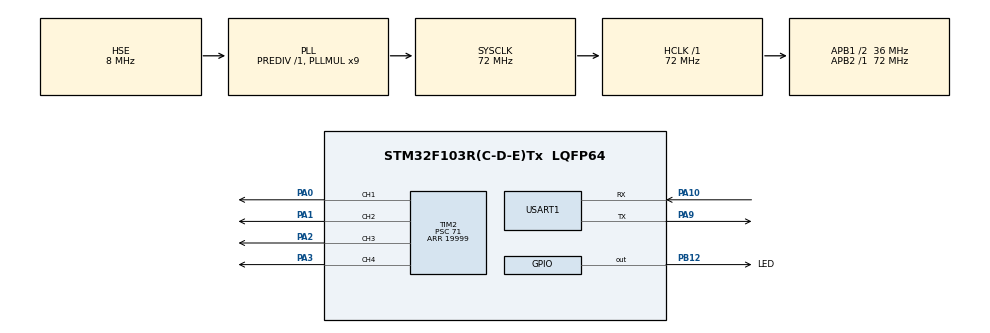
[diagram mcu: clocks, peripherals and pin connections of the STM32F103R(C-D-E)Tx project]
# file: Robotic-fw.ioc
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Dma.Request0=USART1_RX
Dma.Request1=USART1_TX
Dma.USART1_RX.0.Direction=DMA_PERIPH_TO_MEMORY
Dma.USART1_RX.0.Instance=DMA1_Channel5
Dma.USART1_RX.0.MemDataAlignment=DMA_MDATAALIGN_BYTE
Dma.USART1_RX.0.MemInc=DMA_MINC_ENABLE
Dma.USART1_RX.0.Mode=DMA_NORMAL
Dma.USART1_RX.0.PeriphDataAlignment=DMA_PDATAALIGN_BYTE
Dma.USART1_RX.0.PeriphInc=DMA_PINC_DISABLE
Dma.USART1_RX.0.Priority=DMA_PRIORITY_LOW
Dma.USART1_TX.1.Direction=DMA_MEMORY_TO_PERIPH
Dma.USART1_TX.1.Instance=DMA1_Channel4
Dma.USART1_TX.1.MemDataAlignment=DMA_MDATAALIGN_BYTE
Dma.USART1_TX.1.MemInc=DMA_MINC_ENABLE
Dma.USART1_TX.1.Mode=DMA_NORMAL
Dma.USART1_TX.1.PeriphDataAlignment=DMA_PDATAALIGN_BYTE
Dma.USART1_TX.1.PeriphInc=DMA_PINC_DISABLE
Dma.USART1_TX.1.Priority=DMA_PRIORITY_LOW
Mcu.Family=STM32F1
Mcu.Name=STM32F103R(C-D-E)Tx
Mcu.Package=LQFP64
NVIC.DMA1_Channel4_IRQn=true\:0\:0\:false\:false\:true\:false\:true\:true
NVIC.DMA1_Channel5_IRQn=true\:0\:0\:false\:false\:true\:false\:true\:true
NVIC.PriorityGroup=NVIC_PRIORITYGROUP_4
NVIC.USART1_IRQn=true\:0\:0\:false\:false\:true\:false\:true\:true
PA0-WKUP.Signal=S_TIM2_CH1_ETR
PA1.Signal=S_TIM2_CH2
PA10.Mode=Asynchronous
PA10.Signal=USART1_RX
PA13.Mode=Serial_Wire
PA13.Signal=SYS_JTMS-SWDIO
PA14.Mode=Serial_Wire
PA14.Signal=SYS_JTCK-SWCLK
PA2.Signal=S_TIM2_CH3
PA3.Signal=S_TIM2_CH4
PA9.Mode=Asynchronous
PA9.Signal=USART1_TX
PB12.GPIO_Label=LED
PB12.Signal=GPIO_Output
PD0-OSC_IN.Mode=HSE-External-Oscillator
PD0-OSC_IN.Signal=RCC_OSC_IN
PD1-OSC_OUT.Mode=HSE-External-Oscillator
PD1-OSC_OUT.Signal=RCC_OSC_OUT
ProjectManager.HeapSize=0x200
ProjectManager.StackSize=0x400
ProjectManager.TargetToolchain=STM32CubeIDE
RCC.AHBFreq_Value=72000000
RCC.APB1CLKDivider=RCC_HCLK_DIV2
RCC.APB1Freq_Value=36000000
RCC.APB1TimFreq_Value=72000000
RCC.APB2Freq_Value=72000000
RCC.APB2TimFreq_Value=72000000
RCC.DATA_CACHE_ENABLE=0
RCC.HCLKFreq_Value=72000000
RCC.INSTRUCTION_CACHE_ENABLE=0
RCC.PLLMUL=RCC_PLL_MUL9
RCC.PLLSourceVirtual=RCC_PLLSOURCE_HSE
RCC.SYSCLKFreq_VALUE=72000000
RCC.SYSCLKSource=RCC_SYSCLKSOURCE_PLLCLK
RCC.USBFreq_Value=72000000
SH.S_TIM2_CH1_ETR.0=TIM2_CH1,PWM Generation1 CH1
SH.S_TIM2_CH2.0=TIM2_CH2,PWM Generation2 CH2
SH.S_TIM2_CH3.0=TIM2_CH3,PWM Generation3 CH3
SH.S_TIM2_CH4.0=TIM2_CH4,PWM Generation4 CH4
TIM2.Channel-PWM\ Generation1\ CH1=TIM_CHANNEL_1
TIM2.Channel-PWM\ Generation2\ CH2=TIM_CHANNEL_2
TIM2.Channel-PWM\ Generation3\ CH3=TIM_CHANNEL_3
TIM2.Channel-PWM\ Generation4\ CH4=TIM_CHANNEL_4
TIM2.Period=19999
TIM2.Prescaler=71
USART1.VirtualMode=VM_ASYNC
board=custom

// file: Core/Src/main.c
/* USER CODE BEGIN Header */
/**
  ******************************************************************************
  * @file           : main.c
  * @brief          : Main program body
  ******************************************************************************
  * @attention
  *
  * Copyright (c) 2024 STMicroelectronics.
  * All rights reserved.
  *
  * This software is licensed under terms that can be found in the LICENSE file
  * in the root directory of this software component.
  * If no LICENSE file comes with this software, it is provided AS-IS.
  *
  ******************************************************************************
  */
/* USER CODE END Header */
#include "main.h"

/* USER CODE BEGIN PD */
unit8_t USART3_RXbuff;
extern unit8_t center_x, center_y, color_type;
extern double center_x_cm, center_y_cm;
/* USER CODE END PD */

TIM_HandleTypeDef htim2;

UART_HandleTypeDef huart1;
DMA_HandleTypeDef hdma_usart1_rx;
DMA_HandleTypeDef hdma_usart1_tx;

void SystemClock_Config(void);
static void MX_GPIO_Init(void);
static void MX_DMA_Init(void);
static void MX_TIM2_Init(void);
static void MX_USART1_UART_Init(void);

int main(void)
{

  /* MCU Configuration--------------------------------------------------------*/

  /* Reset of all peripherals, Initializes the Flash interface and the Systick. */
  HAL_Init();

  /* Configure the system clock */
  SystemClock_Config();

  /* Initialize all configured peripherals */
  MX_GPIO_Init();
  MX_DMA_Init();
  MX_TIM2_Init();
  MX_USART1_UART_Init();

  /* Infinite loop */
  while (1)
  {

  }
}

void SystemClock_Config(void)
{
  RCC_OscInitTypeDef RCC_OscInitStruct = {0};
  RCC_ClkInitTypeDef RCC_ClkInitStruct = {0};

  /** Initializes the RCC Oscillators according to the specified parameters
  * in the RCC_OscInitTypeDef structure.
  */
  RCC_OscInitStruct.OscillatorType = RCC_OSCILLATORTYPE_HSE;
  RCC_OscInitStruct.HSEState = RCC_HSE_ON;
  RCC_OscInitStruct.HSEPredivValue = RCC_HSE_PREDIV_DIV1;
  RCC_OscInitStruct.HSIState = RCC_HSI_ON;
  RCC_OscInitStruct.PLL.PLLState = RCC_PLL_ON;
  RCC_OscInitStruct.PLL.PLLSource = RCC_PLLSOURCE_HSE;
  RCC_OscInitStruct.PLL.PLLMUL = RCC_PLL_MUL9;
  if (HAL_RCC_OscConfig(&RCC_OscInitStruct) != HAL_OK)
  {
    Error_Handler();
  }

  /** Initializes the CPU, AHB and APB buses clocks
  */
  RCC_ClkInitStruct.ClockType = RCC_CLOCKTYPE_HCLK|RCC_CLOCKTYPE_SYSCLK
                              |RCC_CLOCKTYPE_PCLK1|RCC_CLOCKTYPE_PCLK2;
  RCC_ClkInitStruct.SYSCLKSource = RCC_SYSCLKSOURCE_PLLCLK;
  RCC_ClkInitStruct.AHBCLKDivider = RCC_SYSCLK_DIV1;
  RCC_ClkInitStruct.APB1CLKDivider = RCC_HCLK_DIV2;
  RCC_ClkInitStruct.APB2CLKDivider = RCC_HCLK_DIV1;

  if (HAL_RCC_ClockConfig(&RCC_ClkInitStruct, FLASH_LATENCY_2) != HAL_OK)
  {
    Error_Handler();
  }
}

static void MX_TIM2_Init(void)
{

  TIM_MasterConfigTypeDef sMasterConfig = {0};
  TIM_OC_InitTypeDef sConfigOC = {0};

  htim2.Instance = TIM2;
  htim2.Init.Prescaler = 71;
  htim2.Init.CounterMode = TIM_COUNTERMODE_UP;
  htim2.Init.Period = 19999;
  htim2.Init.ClockDivision = TIM_CLOCKDIVISION_DIV1;
  htim2.Init.AutoReloadPreload = TIM_AUTORELOAD_PRELOAD_DISABLE;
  if (HAL_TIM_PWM_Init(&htim2) != HAL_OK)
  {
    Error_Handler();
  }
  sMasterConfig.MasterOutputTrigger = TIM_TRGO_RESET;
  sMasterConfig.MasterSlaveMode = TIM_MASTERSLAVEMODE_DISABLE;
  if (HAL_TIMEx_MasterConfigSynchronization(&htim2, &sMasterConfig) != HAL_OK)
  {
    Error_Handler();
  }
  sConfigOC.OCMode = TIM_OCMODE_PWM1;
  sConfigOC.Pulse = 0;
  sConfigOC.OCPolarity = TIM_OCPOLARITY_HIGH;
  sConfigOC.OCFastMode = TIM_OCFAST_DISABLE;
  if (HAL_TIM_PWM_ConfigChannel(&htim2, &sConfigOC, TIM_CHANNEL_1) != HAL_OK)
  {
    Error_Handler();
  }
  if (HAL_TIM_PWM_ConfigChannel(&htim2, &sConfigOC, TIM_CHANNEL_2) != HAL_OK)
  {
    Error_Handler();
  }
  if (HAL_TIM_PWM_ConfigChannel(&htim2, &sConfigOC, TIM_CHANNEL_3) != HAL_OK)
  {
    Error_Handler();
  }
  if (HAL_TIM_PWM_ConfigChannel(&htim2, &sConfigOC, TIM_CHANNEL_4) != HAL_OK)
  {
    Error_Handler();
  }
  HAL_TIM_MspPostInit(&htim2);

}

static void MX_USART1_UART_Init(void)
{

  huart1.Instance = USART1;
  huart1.Init.BaudRate = 115200;
  huart1.Init.WordLength = UART_WORDLENGTH_8B;
  huart1.Init.StopBits = UART_STOPBITS_1;
  huart1.Init.Parity = UART_PARITY_NONE;
  huart1.Init.Mode = UART_MODE_TX_RX;
  huart1.Init.HwFlowCtl = UART_HWCONTROL_NONE;
  huart1.Init.OverSampling = UART_OVERSAMPLING_16;
  if (HAL_UART_Init(&huart1) != HAL_OK)
  {
    Error_Handler();
  }

}

static void MX_DMA_Init(void)
{

  /* DMA controller clock enable */
  __HAL_RCC_DMA1_CLK_ENABLE();

  /* DMA interrupt init */
  /* DMA1_Channel4_IRQn interrupt configuration */
  HAL_NVIC_SetPriority(DMA1_Channel4_IRQn, 0, 0);
  HAL_NVIC_EnableIRQ(DMA1_Channel4_IRQn);
  /* DMA1_Channel5_IRQn interrupt configuration */
  HAL_NVIC_SetPriority(DMA1_Channel5_IRQn, 0, 0);
  HAL_NVIC_EnableIRQ(DMA1_Channel5_IRQn);

}

static void MX_GPIO_Init(void)
{
  GPIO_InitTypeDef GPIO_InitStruct = {0};

  /* GPIO Ports Clock Enable */
  __HAL_RCC_GPIOD_CLK_ENABLE();
  __HAL_RCC_GPIOA_CLK_ENABLE();
  __HAL_RCC_GPIOB_CLK_ENABLE();

  /*Configure GPIO pin Output Level */
  HAL_GPIO_WritePin(LED_GPIO_Port, LED_Pin, GPIO_PIN_RESET);

  /*Configure GPIO pin : LED_Pin */
  GPIO_InitStruct.Pin = LED_Pin;
  GPIO_InitStruct.Mode = GPIO_MODE_OUTPUT_PP;
  GPIO_InitStruct.Pull = GPIO_NOPULL;
  GPIO_InitStruct.Speed = GPIO_SPEED_FREQ_LOW;
  HAL_GPIO_Init(LED_GPIO_Port, &GPIO_InitStruct);

}

void Error_Handler(void)
{
  __disable_irq();
  while (1)
  {
  }
}
